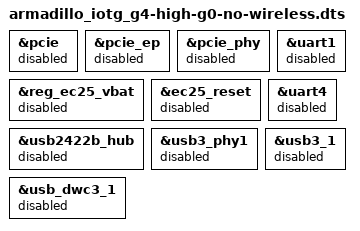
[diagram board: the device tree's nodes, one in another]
// SPDX-License-Identifier: (GPL-2.0 OR MIT)
/*
 * Copyright (C) 2024 Atmark Techno, Inc. All Rights Reserved.
 */

/dts-v1/;
/plugin/;

#include <dt-bindings/gpio/gpio.h>
#include <dt-bindings/clock/imx8mp-clock.h>
#include <dt-bindings/input/input.h>
#include <dt-bindings/interrupt-controller/irq.h>

/* disable wlan */
&pcie {
	status = "broken";
};

&pcie_ep {
	status = "broken";
};

&pcie_phy {
	status = "broken";
};

/* disable bt */
&uart1 {
	status = "broken";
};

/* disable lte */
&reg_ec25_vbat {
	status = "broken";
};

&ec25_reset {
	status = "broken";
};

&uart4 {
	status = "broken";
};

&usb2422b_hub {
	status = "broken";
};

&usb3_phy1 {
	status = "broken";
};

&usb3_1 {
	status = "broken";
};

&usb_dwc3_1 {
	status = "broken";
};
